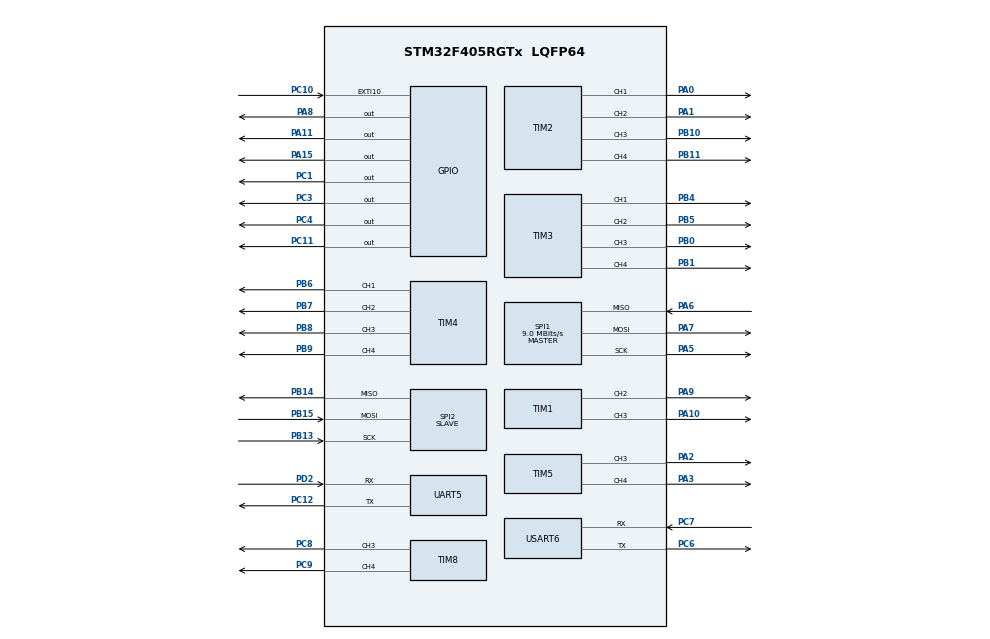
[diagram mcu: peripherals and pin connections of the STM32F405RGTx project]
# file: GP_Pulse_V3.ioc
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Mcu.Family=STM32F4
Mcu.Name=STM32F405RGTx
Mcu.Package=LQFP64
NVIC.EXTI15_10_IRQn=true\:9\:0\:true\:false\:true\:true\:true\:true
NVIC.PriorityGroup=NVIC_PRIORITYGROUP_4
NVIC.SPI1_IRQn=true\:10\:0\:true\:false\:true\:true\:true\:true
NVIC.TIM2_IRQn=true\:11\:0\:true\:false\:true\:true\:true\:true
NVIC.TIM3_IRQn=true\:11\:0\:true\:false\:true\:true\:true\:true
NVIC.TIM4_IRQn=true\:11\:0\:true\:false\:true\:true\:true\:true
NVIC.TIM5_IRQn=true\:11\:0\:true\:false\:true\:true\:true\:true
NVIC.TIM6_DAC_IRQn=true\:9\:0\:true\:false\:true\:true\:true\:true
NVIC.TIM7_IRQn=true\:12\:0\:true\:false\:true\:true\:true\:true
NVIC.TIM8_TRG_COM_TIM14_IRQn=true\:15\:0\:false\:false\:true\:false\:true\:true
NVIC.TIM8_UP_TIM13_IRQn=true\:11\:0\:true\:false\:true\:true\:true\:true
NVIC.TimeBase=TIM8_TRG_COM_TIM14_IRQn
NVIC.TimeBaseIP=TIM14
NVIC.UART5_IRQn=true\:14\:0\:true\:false\:true\:true\:true\:true
NVIC.USART6_IRQn=true\:14\:0\:true\:false\:true\:true\:true\:true
PA0-WKUP.Signal=S_TIM2_CH1_ETR
PA1.Signal=S_TIM2_CH2
PA10.Signal=S_TIM1_CH3
PA11.GPIO_PuPd=GPIO_PULLDOWN
PA11.Signal=GPIO_Output
PA13.Mode=Serial_Wire
PA13.Signal=SYS_JTMS-SWDIO
PA14.Mode=Serial_Wire
PA14.Signal=SYS_JTCK-SWCLK
PA15.GPIO_PuPd=GPIO_PULLDOWN
PA15.Signal=GPIO_Output
PA2.Signal=S_TIM5_CH3
PA3.Signal=S_TIM5_CH4
PA5.Mode=Full_Duplex_Master
PA5.Signal=SPI1_SCK
PA6.Mode=Full_Duplex_Master
PA6.Signal=SPI1_MISO
PA7.Mode=Full_Duplex_Master
PA7.Signal=SPI1_MOSI
PA8.GPIO_PuPd=GPIO_PULLDOWN
PA8.Signal=GPIO_Output
PA9.Signal=S_TIM1_CH2
PB0.Signal=S_TIM3_CH3
PB1.Signal=S_TIM3_CH4
PB10.Signal=S_TIM2_CH3
PB11.Signal=S_TIM2_CH4
PB13.Mode=Full_Duplex_Slave
PB13.Signal=SPI2_SCK
PB14.Mode=Full_Duplex_Slave
PB14.Signal=SPI2_MISO
PB15.Mode=Full_Duplex_Slave
PB15.Signal=SPI2_MOSI
PB4.Signal=S_TIM3_CH1
PB5.Signal=S_TIM3_CH2
PB6.Signal=S_TIM4_CH1
PB7.Signal=S_TIM4_CH2
PB8.Signal=S_TIM4_CH3
PB9.Signal=S_TIM4_CH4
PC1.GPIO_PuPd=GPIO_PULLDOWN
PC1.Signal=GPIO_Output
PC10.GPIO_ModeDefaultEXTI=GPIO_MODE_IT_FALLING
PC10.GPIO_PuPd=GPIO_PULLUP
PC10.Signal=GPXTI10
PC11.GPIO_PuPd=GPIO_PULLDOWN
PC11.Signal=GPIO_Output
PC12.Mode=Asynchronous
PC12.Signal=UART5_TX
PC3.GPIO_PuPd=GPIO_PULLDOWN
PC3.Signal=GPIO_Output
PC4.GPIO_PuPd=GPIO_PULLUP
PC4.GPIO_Speed=GPIO_SPEED_FREQ_VERY_HIGH
PC4.PinState=GPIO_PIN_SET
PC4.Signal=GPIO_Output
PC6.Mode=Asynchronous
PC6.Signal=USART6_TX
PC7.Mode=Asynchronous
PC7.Signal=USART6_RX
PC8.Signal=S_TIM8_CH3
PC9.Signal=S_TIM8_CH4
PD2.Mode=Asynchronous
PD2.Signal=UART5_RX
PH0-OSC_IN.Mode=HSE-External-Oscillator
PH0-OSC_IN.Signal=RCC_OSC_IN
PH1-OSC_OUT.Mode=HSE-External-Oscillator
PH1-OSC_OUT.Signal=RCC_OSC_OUT
ProjectManager.HeapSize=0x200
ProjectManager.StackSize=0x400
ProjectManager.TargetToolchain=STM32CubeIDE
RCC.48MHZClocksFreq_Value=36000000
RCC.AHBFreq_Value=72000000
RCC.APB1CLKDivider=RCC_HCLK_DIV2
RCC.APB1Freq_Value=36000000
RCC.APB1TimFreq_Value=72000000
RCC.APB2Freq_Value=72000000
RCC.APB2TimFreq_Value=72000000
RCC.CortexFreq_Value=72000000
RCC.HCLKFreq_Value=72000000
RCC.HSE_VALUE=8000000
RCC.HSI_VALUE=16000000
RCC.LSE_VALUE=32768
RCC.PLLM=4
RCC.PLLN=72
RCC.PLLSourceVirtual=RCC_PLLSOURCE_HSE
RCC.SYSCLKFreq_VALUE=72000000
RCC.SYSCLKSource=RCC_SYSCLKSOURCE_PLLCLK
RCC.VCOOutputFreq_Value=144000000
SH.S_TIM1_CH2.0=TIM1_CH2,PWM Generation2 CH2
SH.S_TIM1_CH3.0=TIM1_CH3,PWM Generation3 CH3
SH.S_TIM2_CH1_ETR.0=TIM2_CH1,PWM Generation1 CH1
SH.S_TIM2_CH2.0=TIM2_CH2,PWM Generation2 CH2
SH.S_TIM2_CH3.0=TIM2_CH3,PWM Generation3 CH3
SH.S_TIM2_CH4.0=TIM2_CH4,PWM Generation4 CH4
SH.S_TIM3_CH1.0=TIM3_CH1,PWM Generation1 CH1
SH.S_TIM3_CH2.0=TIM3_CH2,PWM Generation2 CH2
SH.S_TIM3_CH3.0=TIM3_CH3,PWM Generation3 CH3
SH.S_TIM3_CH4.0=TIM3_CH4,PWM Generation4 CH4
SH.S_TIM4_CH1.0=TIM4_CH1,PWM Generation1 CH1
SH.S_TIM4_CH2.0=TIM4_CH2,PWM Generation2 CH2
SH.S_TIM4_CH3.0=TIM4_CH3,PWM Generation3 CH3
SH.S_TIM4_CH4.0=TIM4_CH4,PWM Generation4 CH4
SH.S_TIM5_CH3.0=TIM5_CH3,PWM Generation3 CH3
SH.S_TIM5_CH4.0=TIM5_CH4,PWM Generation4 CH4
SH.S_TIM8_CH3.0=TIM8_CH3,Output Compare3 CH3
SH.S_TIM8_CH4.0=TIM8_CH4,PWM Generation4 CH4
SPI1.BaudRatePrescaler=SPI_BAUDRATEPRESCALER_8
SPI1.CLKPhase=SPI_PHASE_2EDGE
SPI1.CalculateBaudRate=9.0 MBits/s
SPI1.Direction=SPI_DIRECTION_2LINES
SPI1.Mode=SPI_MODE_MASTER
SPI1.VirtualType=VM_MASTER
SPI2.Direction=SPI_DIRECTION_2LINES
SPI2.Mode=SPI_MODE_SLAVE
SPI2.VirtualType=VM_SLAVE
TIM1.Channel-PWM\ Generation2\ CH2=TIM_CHANNEL_2
TIM1.Channel-PWM\ Generation3\ CH3=TIM_CHANNEL_3
TIM2.Channel-PWM\ Generation1\ CH1=TIM_CHANNEL_1
TIM2.Channel-PWM\ Generation2\ CH2=TIM_CHANNEL_2
TIM2.Channel-PWM\ Generation3\ CH3=TIM_CHANNEL_3
TIM2.Channel-PWM\ Generation4\ CH4=TIM_CHANNEL_4
TIM3.Channel-PWM\ Generation1\ CH1=TIM_CHANNEL_1
TIM3.Channel-PWM\ Generation2\ CH2=TIM_CHANNEL_2
TIM3.Channel-PWM\ Generation3\ CH3=TIM_CHANNEL_3
TIM3.Channel-PWM\ Generation4\ CH4=TIM_CHANNEL_4
TIM4.Channel-PWM\ Generation1\ CH1=TIM_CHANNEL_1
TIM4.Channel-PWM\ Generation2\ CH2=TIM_CHANNEL_2
TIM4.Channel-PWM\ Generation3\ CH3=TIM_CHANNEL_3
TIM4.Channel-PWM\ Generation4\ CH4=TIM_CHANNEL_4
TIM5.Channel-PWM\ Generation3\ CH3=TIM_CHANNEL_3
TIM5.Channel-PWM\ Generation4\ CH4=TIM_CHANNEL_4
TIM8.Channel-Output\ Compare3\ CH3=TIM_CHANNEL_3
TIM8.Channel-PWM\ Generation4\ CH4=TIM_CHANNEL_4
UART5.VirtualMode=Asynchronous
USART6.VirtualMode=VM_ASYNC
VP_SYS_VS_tim14.Mode=TIM14
VP_TIM6_VS_ClockSourceINT.Mode=Enable_Timer
VP_TIM7_VS_ClockSourceINT.Mode=Enable_Timer
board=custom

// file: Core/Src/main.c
/* USER CODE BEGIN Header */
/**
  ******************************************************************************
  * @file           : main.c
  * @brief          : Main program body
  ******************************************************************************
  * @attention
  *
  * Copyright (c) 2025 STMicroelectronics.
  * All rights reserved.
  *
  * This software is licensed under terms that can be found in the LICENSE file
  * in the root directory of this software component.
  * If no LICENSE file comes with this software, it is provided AS-IS.
  *
  ******************************************************************************
  */
/* USER CODE END Header */
#include "main.h"

/* USER CODE BEGIN Includes */
#include "app.h"
/* USER CODE END Includes */

void SystemClock_Config(void);
static void MX_GPIO_Init(void);
static void MX_SPI1_Init(void);
static void MX_SPI2_Init(void);
static void MX_TIM1_Init(void);
static void MX_TIM2_Init(void);
static void MX_TIM3_Init(void);
static void MX_TIM4_Init(void);
static void MX_TIM5_Init(void);
static void MX_TIM8_Init(void);
static void MX_UART5_Init(void);
static void MX_USART6_UART_Init(void);
static void MX_TIM6_Init(void);
static void MX_TIM7_Init(void);

int main(void)
{

  /* MCU Configuration--------------------------------------------------------*/

  /* Reset of all peripherals, Initializes the Flash interface and the Systick. */
  HAL_Init();

  /* Configure the system clock */
  SystemClock_Config();

  /* Initialize all configured peripherals */
  MX_GPIO_Init();
  MX_SPI1_Init();
  MX_SPI2_Init();
  MX_TIM1_Init();
  MX_TIM2_Init();
  MX_TIM3_Init();
  MX_TIM4_Init();
  MX_TIM5_Init();
  MX_TIM8_Init();
  MX_UART5_Init();
  MX_USART6_UART_Init();
  MX_TIM6_Init();
  MX_TIM7_Init();
  /* USER CODE BEGIN 2 */
  App_Main();
  /* USER CODE END 2 */

  /* Infinite loop */
  while (1)
  {

  }
}

void SystemClock_Config(void)
{
  LL_FLASH_SetLatency(LL_FLASH_LATENCY_2);
  while(LL_FLASH_GetLatency()!= LL_FLASH_LATENCY_2)
  {
  }
  LL_PWR_SetRegulVoltageScaling(LL_PWR_REGU_VOLTAGE_SCALE1);
  LL_RCC_HSE_Enable();

   /* Wait till HSE is ready */
  while(LL_RCC_HSE_IsReady() != 1)
  {

  }
  LL_RCC_PLL_ConfigDomain_SYS(LL_RCC_PLLSOURCE_HSE, LL_RCC_PLLM_DIV_4, 72, LL_RCC_PLLP_DIV_2);
  LL_RCC_PLL_Enable();

   /* Wait till PLL is ready */
  while(LL_RCC_PLL_IsReady() != 1)
  {

  }
  while (LL_PWR_IsActiveFlag_VOS() == 0)
  {
  }
  LL_RCC_SetAHBPrescaler(LL_RCC_SYSCLK_DIV_1);
  LL_RCC_SetAPB1Prescaler(LL_RCC_APB1_DIV_2);
  LL_RCC_SetAPB2Prescaler(LL_RCC_APB2_DIV_1);
  LL_RCC_SetSysClkSource(LL_RCC_SYS_CLKSOURCE_PLL);

   /* Wait till System clock is ready */
  while(LL_RCC_GetSysClkSource() != LL_RCC_SYS_CLKSOURCE_STATUS_PLL)
  {

  }
  LL_SetSystemCoreClock(72000000);

   /* Update the time base */
  if (HAL_InitTick (TICK_INT_PRIORITY) != HAL_OK)
  {
    Error_Handler();
  }
}

static void MX_SPI1_Init(void)
{

  LL_SPI_InitTypeDef SPI_InitStruct = {0};

  LL_GPIO_InitTypeDef GPIO_InitStruct = {0};

  /* Peripheral clock enable */
  LL_APB2_GRP1_EnableClock(LL_APB2_GRP1_PERIPH_SPI1);

  LL_AHB1_GRP1_EnableClock(LL_AHB1_GRP1_PERIPH_GPIOA);
  /**SPI1 GPIO Configuration
  PA5   ------> SPI1_SCK
  PA6   ------> SPI1_MISO
  PA7   ------> SPI1_MOSI
  */
  GPIO_InitStruct.Pin = LL_GPIO_PIN_5|LL_GPIO_PIN_6|LL_GPIO_PIN_7;
  GPIO_InitStruct.Mode = LL_GPIO_MODE_ALTERNATE;
  GPIO_InitStruct.Speed = LL_GPIO_SPEED_FREQ_VERY_HIGH;
  GPIO_InitStruct.OutputType = LL_GPIO_OUTPUT_PUSHPULL;
  GPIO_InitStruct.Pull = LL_GPIO_PULL_NO;
  GPIO_InitStruct.Alternate = LL_GPIO_AF_5;
  LL_GPIO_Init(GPIOA, &GPIO_InitStruct);

  /* SPI1 interrupt Init */
  NVIC_SetPriority(SPI1_IRQn, NVIC_EncodePriority(NVIC_GetPriorityGrouping(),10, 0));
  NVIC_EnableIRQ(SPI1_IRQn);

  /* SPI1 parameter configuration*/
  SPI_InitStruct.TransferDirection = LL_SPI_FULL_DUPLEX;
  SPI_InitStruct.Mode = LL_SPI_MODE_MASTER;
  SPI_InitStruct.DataWidth = LL_SPI_DATAWIDTH_8BIT;
  SPI_InitStruct.ClockPolarity = LL_SPI_POLARITY_LOW;
  SPI_InitStruct.ClockPhase = LL_SPI_PHASE_2EDGE;
  SPI_InitStruct.NSS = LL_SPI_NSS_SOFT;
  SPI_InitStruct.BaudRate = LL_SPI_BAUDRATEPRESCALER_DIV8;
  SPI_InitStruct.BitOrder = LL_SPI_MSB_FIRST;
  SPI_InitStruct.CRCCalculation = LL_SPI_CRCCALCULATION_DISABLE;
  SPI_InitStruct.CRCPoly = 10;
  LL_SPI_Init(SPI1, &SPI_InitStruct);
  LL_SPI_SetStandard(SPI1, LL_SPI_PROTOCOL_MOTOROLA);

}

static void MX_SPI2_Init(void)
{

  LL_SPI_InitTypeDef SPI_InitStruct = {0};

  LL_GPIO_InitTypeDef GPIO_InitStruct = {0};

  /* Peripheral clock enable */
  LL_APB1_GRP1_EnableClock(LL_APB1_GRP1_PERIPH_SPI2);

  LL_AHB1_GRP1_EnableClock(LL_AHB1_GRP1_PERIPH_GPIOB);
  /**SPI2 GPIO Configuration
  PB13   ------> SPI2_SCK
  PB14   ------> SPI2_MISO
  PB15   ------> SPI2_MOSI
  */
  GPIO_InitStruct.Pin = LL_GPIO_PIN_13|LL_GPIO_PIN_14|LL_GPIO_PIN_15;
  GPIO_InitStruct.Mode = LL_GPIO_MODE_ALTERNATE;
  GPIO_InitStruct.Speed = LL_GPIO_SPEED_FREQ_VERY_HIGH;
  GPIO_InitStruct.OutputType = LL_GPIO_OUTPUT_PUSHPULL;
  GPIO_InitStruct.Pull = LL_GPIO_PULL_NO;
  GPIO_InitStruct.Alternate = LL_GPIO_AF_5;
  LL_GPIO_Init(GPIOB, &GPIO_InitStruct);

  /* SPI2 parameter configuration*/
  SPI_InitStruct.TransferDirection = LL_SPI_FULL_DUPLEX;
  SPI_InitStruct.Mode = LL_SPI_MODE_SLAVE;
  SPI_InitStruct.DataWidth = LL_SPI_DATAWIDTH_8BIT;
  SPI_InitStruct.ClockPolarity = LL_SPI_POLARITY_LOW;
  SPI_InitStruct.ClockPhase = LL_SPI_PHASE_1EDGE;
  SPI_InitStruct.NSS = LL_SPI_NSS_SOFT;
  SPI_InitStruct.BitOrder = LL_SPI_MSB_FIRST;
  SPI_InitStruct.CRCCalculation = LL_SPI_CRCCALCULATION_DISABLE;
  SPI_InitStruct.CRCPoly = 10;
  LL_SPI_Init(SPI2, &SPI_InitStruct);
  LL_SPI_SetStandard(SPI2, LL_SPI_PROTOCOL_MOTOROLA);

}

static void MX_TIM1_Init(void)
{

  LL_TIM_InitTypeDef TIM_InitStruct = {0};
  LL_TIM_OC_InitTypeDef TIM_OC_InitStruct = {0};
  LL_TIM_BDTR_InitTypeDef TIM_BDTRInitStruct = {0};

  LL_GPIO_InitTypeDef GPIO_InitStruct = {0};

  /* Peripheral clock enable */
  LL_APB2_GRP1_EnableClock(LL_APB2_GRP1_PERIPH_TIM1);

  TIM_InitStruct.Prescaler = 0;
  TIM_InitStruct.CounterMode = LL_TIM_COUNTERMODE_UP;
  TIM_InitStruct.Autoreload = 65535;
  TIM_InitStruct.ClockDivision = LL_TIM_CLOCKDIVISION_DIV1;
  TIM_InitStruct.RepetitionCounter = 0;
  LL_TIM_Init(TIM1, &TIM_InitStruct);
  LL_TIM_DisableARRPreload(TIM1);
  LL_TIM_OC_EnablePreload(TIM1, LL_TIM_CHANNEL_CH2);
  TIM_OC_InitStruct.OCMode = LL_TIM_OCMODE_PWM1;
  TIM_OC_InitStruct.OCState = LL_TIM_OCSTATE_DISABLE;
  TIM_OC_InitStruct.OCNState = LL_TIM_OCSTATE_DISABLE;
  TIM_OC_InitStruct.CompareValue = 0;
  TIM_OC_InitStruct.OCPolarity = LL_TIM_OCPOLARITY_HIGH;
  TIM_OC_InitStruct.OCNPolarity = LL_TIM_OCPOLARITY_HIGH;
  TIM_OC_InitStruct.OCIdleState = LL_TIM_OCIDLESTATE_LOW;
  TIM_OC_InitStruct.OCNIdleState = LL_TIM_OCIDLESTATE_LOW;
  LL_TIM_OC_Init(TIM1, LL_TIM_CHANNEL_CH2, &TIM_OC_InitStruct);
  LL_TIM_OC_DisableFast(TIM1, LL_TIM_CHANNEL_CH2);
  LL_TIM_OC_EnablePreload(TIM1, LL_TIM_CHANNEL_CH3);
  LL_TIM_OC_Init(TIM1, LL_TIM_CHANNEL_CH3, &TIM_OC_InitStruct);
  LL_TIM_OC_DisableFast(TIM1, LL_TIM_CHANNEL_CH3);
  LL_TIM_SetTriggerOutput(TIM1, LL_TIM_TRGO_RESET);
  LL_TIM_DisableMasterSlaveMode(TIM1);
  TIM_BDTRInitStruct.OSSRState = LL_TIM_OSSR_DISABLE;
  TIM_BDTRInitStruct.OSSIState = LL_TIM_OSSI_DISABLE;
  TIM_BDTRInitStruct.LockLevel = LL_TIM_LOCKLEVEL_OFF;
  TIM_BDTRInitStruct.DeadTime = 0;
  TIM_BDTRInitStruct.BreakState = LL_TIM_BREAK_DISABLE;
  TIM_BDTRInitStruct.BreakPolarity = LL_TIM_BREAK_POLARITY_HIGH;
  TIM_BDTRInitStruct.AutomaticOutput = LL_TIM_AUTOMATICOUTPUT_DISABLE;
  LL_TIM_BDTR_Init(TIM1, &TIM_BDTRInitStruct);
  LL_AHB1_GRP1_EnableClock(LL_AHB1_GRP1_PERIPH_GPIOA);
  /**TIM1 GPIO Configuration
  PA9   ------> TIM1_CH2
  PA10   ------> TIM1_CH3
  */
  GPIO_InitStruct.Pin = LL_GPIO_PIN_9|LL_GPIO_PIN_10;
  GPIO_InitStruct.Mode = LL_GPIO_MODE_ALTERNATE;
  GPIO_InitStruct.Speed = LL_GPIO_SPEED_FREQ_LOW;
  GPIO_InitStruct.OutputType = LL_GPIO_OUTPUT_PUSHPULL;
  GPIO_InitStruct.Pull = LL_GPIO_PULL_NO;
  GPIO_InitStruct.Alternate = LL_GPIO_AF_1;
  LL_GPIO_Init(GPIOA, &GPIO_InitStruct);

}

static void MX_TIM2_Init(void)
{

  LL_TIM_InitTypeDef TIM_InitStruct = {0};
  LL_TIM_OC_InitTypeDef TIM_OC_InitStruct = {0};

  LL_GPIO_InitTypeDef GPIO_InitStruct = {0};

  /* Peripheral clock enable */
  LL_APB1_GRP1_EnableClock(LL_APB1_GRP1_PERIPH_TIM2);

  /* TIM2 interrupt Init */
  NVIC_SetPriority(TIM2_IRQn, NVIC_EncodePriority(NVIC_GetPriorityGrouping(),11, 0));
  NVIC_EnableIRQ(TIM2_IRQn);

  TIM_InitStruct.Prescaler = 0;
  TIM_InitStruct.CounterMode = LL_TIM_COUNTERMODE_UP;
  TIM_InitStruct.Autoreload = 4294967295;
  TIM_InitStruct.ClockDivision = LL_TIM_CLOCKDIVISION_DIV1;
  LL_TIM_Init(TIM2, &TIM_InitStruct);
  LL_TIM_DisableARRPreload(TIM2);
  LL_TIM_OC_EnablePreload(TIM2, LL_TIM_CHANNEL_CH1);
  TIM_OC_InitStruct.OCMode = LL_TIM_OCMODE_PWM1;
  TIM_OC_InitStruct.OCState = LL_TIM_OCSTATE_DISABLE;
  TIM_OC_InitStruct.OCNState = LL_TIM_OCSTATE_DISABLE;
  TIM_OC_InitStruct.CompareValue = 0;
  TIM_OC_InitStruct.OCPolarity = LL_TIM_OCPOLARITY_HIGH;
  LL_TIM_OC_Init(TIM2, LL_TIM_CHANNEL_CH1, &TIM_OC_InitStruct);
  LL_TIM_OC_DisableFast(TIM2, LL_TIM_CHANNEL_CH1);
  LL_TIM_OC_EnablePreload(TIM2, LL_TIM_CHANNEL_CH2);
  LL_TIM_OC_Init(TIM2, LL_TIM_CHANNEL_CH2, &TIM_OC_InitStruct);
  LL_TIM_OC_DisableFast(TIM2, LL_TIM_CHANNEL_CH2);
  LL_TIM_OC_EnablePreload(TIM2, LL_TIM_CHANNEL_CH3);
  LL_TIM_OC_Init(TIM2, LL_TIM_CHANNEL_CH3, &TIM_OC_InitStruct);
  LL_TIM_OC_DisableFast(TIM2, LL_TIM_CHANNEL_CH3);
  LL_TIM_OC_EnablePreload(TIM2, LL_TIM_CHANNEL_CH4);
  LL_TIM_OC_Init(TIM2, LL_TIM_CHANNEL_CH4, &TIM_OC_InitStruct);
  LL_TIM_OC_DisableFast(TIM2, LL_TIM_CHANNEL_CH4);
  LL_TIM_SetTriggerOutput(TIM2, LL_TIM_TRGO_RESET);
  LL_TIM_DisableMasterSlaveMode(TIM2);
  LL_AHB1_GRP1_EnableClock(LL_AHB1_GRP1_PERIPH_GPIOA);
  LL_AHB1_GRP1_EnableClock(LL_AHB1_GRP1_PERIPH_GPIOB);
  /**TIM2 GPIO Configuration
  PA0-WKUP   ------> TIM2_CH1
  PA1   ------> TIM2_CH2
  PB10   ------> TIM2_CH3
  PB11   ------> TIM2_CH4
  */
  GPIO_InitStruct.Pin = LL_GPIO_PIN_0|LL_GPIO_PIN_1;
  GPIO_InitStruct.Mode = LL_GPIO_MODE_ALTERNATE;
  GPIO_InitStruct.Speed = LL_GPIO_SPEED_FREQ_LOW;
  GPIO_InitStruct.OutputType = LL_GPIO_OUTPUT_PUSHPULL;
  GPIO_InitStruct.Pull = LL_GPIO_PULL_NO;
  GPIO_InitStruct.Alternate = LL_GPIO_AF_1;
  LL_GPIO_Init(GPIOA, &GPIO_InitStruct);

  GPIO_InitStruct.Pin = LL_GPIO_PIN_10|LL_GPIO_PIN_11;
  GPIO_InitStruct.Mode = LL_GPIO_MODE_ALTERNATE;
  GPIO_InitStruct.Speed = LL_GPIO_SPEED_FREQ_LOW;
  GPIO_InitStruct.OutputType = LL_GPIO_OUTPUT_PUSHPULL;
  GPIO_InitStruct.Pull = LL_GPIO_PULL_NO;
  GPIO_InitStruct.Alternate = LL_GPIO_AF_1;
  LL_GPIO_Init(GPIOB, &GPIO_InitStruct);

}

static void MX_TIM3_Init(void)
{

  LL_TIM_InitTypeDef TIM_InitStruct = {0};
  LL_TIM_OC_InitTypeDef TIM_OC_InitStruct = {0};

  LL_GPIO_InitTypeDef GPIO_InitStruct = {0};

  /* Peripheral clock enable */
  LL_APB1_GRP1_EnableClock(LL_APB1_GRP1_PERIPH_TIM3);

  /* TIM3 interrupt Init */
  NVIC_SetPriority(TIM3_IRQn, NVIC_EncodePriority(NVIC_GetPriorityGrouping(),11, 0));
  NVIC_EnableIRQ(TIM3_IRQn);

  TIM_InitStruct.Prescaler = 0;
  TIM_InitStruct.CounterMode = LL_TIM_COUNTERMODE_UP;
  TIM_InitStruct.Autoreload = 65535;
  TIM_InitStruct.ClockDivision = LL_TIM_CLOCKDIVISION_DIV1;
  LL_TIM_Init(TIM3, &TIM_InitStruct);
  LL_TIM_DisableARRPreload(TIM3);
  LL_TIM_OC_EnablePreload(TIM3, LL_TIM_CHANNEL_CH1);
  TIM_OC_InitStruct.OCMode = LL_TIM_OCMODE_PWM1;
  TIM_OC_InitStruct.OCState = LL_TIM_OCSTATE_DISABLE;
  TIM_OC_InitStruct.OCNState = LL_TIM_OCSTATE_DISABLE;
  TIM_OC_InitStruct.CompareValue = 0;
  TIM_OC_InitStruct.OCPolarity = LL_TIM_OCPOLARITY_HIGH;
  LL_TIM_OC_Init(TIM3, LL_TIM_CHANNEL_CH1, &TIM_OC_InitStruct);
  LL_TIM_OC_DisableFast(TIM3, LL_TIM_CHANNEL_CH1);
  LL_TIM_OC_EnablePreload(TIM3, LL_TIM_CHANNEL_CH2);
  LL_TIM_OC_Init(TIM3, LL_TIM_CHANNEL_CH2, &TIM_OC_InitStruct);
  LL_TIM_OC_DisableFast(TIM3, LL_TIM_CHANNEL_CH2);
  LL_TIM_OC_EnablePreload(TIM3, LL_TIM_CHANNEL_CH3);
  LL_TIM_OC_Init(TIM3, LL_TIM_CHANNEL_CH3, &TIM_OC_InitStruct);
  LL_TIM_OC_DisableFast(TIM3, LL_TIM_CHANNEL_CH3);
  LL_TIM_OC_EnablePreload(TIM3, LL_TIM_CHANNEL_CH4);
  LL_TIM_OC_Init(TIM3, LL_TIM_CHANNEL_CH4, &TIM_OC_InitStruct);
  LL_TIM_OC_DisableFast(TIM3, LL_TIM_CHANNEL_CH4);
  LL_TIM_SetTriggerOutput(TIM3, LL_TIM_TRGO_RESET);
  LL_TIM_DisableMasterSlaveMode(TIM3);
  LL_AHB1_GRP1_EnableClock(LL_AHB1_GRP1_PERIPH_GPIOB);
  /**TIM3 GPIO Configuration
  PB0   ------> TIM3_CH3
  PB1   ------> TIM3_CH4
  PB4   ------> TIM3_CH1
  PB5   ------> TIM3_CH2
  */
  GPIO_InitStruct.Pin = LL_GPIO_PIN_0|LL_GPIO_PIN_1|LL_GPIO_PIN_4|LL_GPIO_PIN_5;
  GPIO_InitStruct.Mode = LL_GPIO_MODE_ALTERNATE;
  GPIO_InitStruct.Speed = LL_GPIO_SPEED_FREQ_LOW;
  GPIO_InitStruct.OutputType = LL_GPIO_OUTPUT_PUSHPULL;
  GPIO_InitStruct.Pull = LL_GPIO_PULL_NO;
  GPIO_InitStruct.Alternate = LL_GPIO_AF_2;
  LL_GPIO_Init(GPIOB, &GPIO_InitStruct);

}

static void MX_TIM4_Init(void)
{

  LL_TIM_InitTypeDef TIM_InitStruct = {0};
  LL_TIM_OC_InitTypeDef TIM_OC_InitStruct = {0};

  LL_GPIO_InitTypeDef GPIO_InitStruct = {0};

  /* Peripheral clock enable */
  LL_APB1_GRP1_EnableClock(LL_APB1_GRP1_PERIPH_TIM4);

  /* TIM4 interrupt Init */
  NVIC_SetPriority(TIM4_IRQn, NVIC_EncodePriority(NVIC_GetPriorityGrouping(),11, 0));
  NVIC_EnableIRQ(TIM4_IRQn);

  TIM_InitStruct.Prescaler = 0;
  TIM_InitStruct.CounterMode = LL_TIM_COUNTERMODE_UP;
  TIM_InitStruct.Autoreload = 65535;
  TIM_InitStruct.ClockDivision = LL_TIM_CLOCKDIVISION_DIV1;
  LL_TIM_Init(TIM4, &TIM_InitStruct);
  LL_TIM_DisableARRPreload(TIM4);
  LL_TIM_OC_EnablePreload(TIM4, LL_TIM_CHANNEL_CH1);
  TIM_OC_InitStruct.OCMode = LL_TIM_OCMODE_PWM1;
  TIM_OC_InitStruct.OCState = LL_TIM_OCSTATE_DISABLE;
  TIM_OC_InitStruct.OCNState = LL_TIM_OCSTATE_DISABLE;
  TIM_OC_InitStruct.CompareValue = 0;
  TIM_OC_InitStruct.OCPolarity = LL_TIM_OCPOLARITY_HIGH;
  LL_TIM_OC_Init(TIM4, LL_TIM_CHANNEL_CH1, &TIM_OC_InitStruct);
  LL_TIM_OC_DisableFast(TIM4, LL_TIM_CHANNEL_CH1);
  LL_TIM_OC_EnablePreload(TIM4, LL_TIM_CHANNEL_CH2);
  LL_TIM_OC_Init(TIM4, LL_TIM_CHANNEL_CH2, &TIM_OC_InitStruct);
  LL_TIM_OC_DisableFast(TIM4, LL_TIM_CHANNEL_CH2);
  LL_TIM_OC_EnablePreload(TIM4, LL_TIM_CHANNEL_CH3);
  LL_TIM_OC_Init(TIM4, LL_TIM_CHANNEL_CH3, &TIM_OC_InitStruct);
  LL_TIM_OC_DisableFast(TIM4, LL_TIM_CHANNEL_CH3);
  LL_TIM_OC_EnablePreload(TIM4, LL_TIM_CHANNEL_CH4);
  LL_TIM_OC_Init(TIM4, LL_TIM_CHANNEL_CH4, &TIM_OC_InitStruct);
  LL_TIM_OC_DisableFast(TIM4, LL_TIM_CHANNEL_CH4);
  LL_TIM_SetTriggerOutput(TIM4, LL_TIM_TRGO_RESET);
  LL_TIM_DisableMasterSlaveMode(TIM4);
  LL_AHB1_GRP1_EnableClock(LL_AHB1_GRP1_PERIPH_GPIOB);
  /**TIM4 GPIO Configuration
  PB6   ------> TIM4_CH1
  PB7   ------> TIM4_CH2
  PB8   ------> TIM4_CH3
  PB9   ------> TIM4_CH4
  */
  GPIO_InitStruct.Pin = LL_GPIO_PIN_6|LL_GPIO_PIN_7|LL_GPIO_PIN_8|LL_GPIO_PIN_9;
  GPIO_InitStruct.Mode = LL_GPIO_MODE_ALTERNATE;
  GPIO_InitStruct.Speed = LL_GPIO_SPEED_FREQ_LOW;
  GPIO_InitStruct.OutputType = LL_GPIO_OUTPUT_PUSHPULL;
  GPIO_InitStruct.Pull = LL_GPIO_PULL_NO;
  GPIO_InitStruct.Alternate = LL_GPIO_AF_2;
  LL_GPIO_Init(GPIOB, &GPIO_InitStruct);

}

static void MX_TIM5_Init(void)
{

  LL_TIM_InitTypeDef TIM_InitStruct = {0};
  LL_TIM_OC_InitTypeDef TIM_OC_InitStruct = {0};

  LL_GPIO_InitTypeDef GPIO_InitStruct = {0};

  /* Peripheral clock enable */
  LL_APB1_GRP1_EnableClock(LL_APB1_GRP1_PERIPH_TIM5);

  /* TIM5 interrupt Init */
  NVIC_SetPriority(TIM5_IRQn, NVIC_EncodePriority(NVIC_GetPriorityGrouping(),11, 0));
  NVIC_EnableIRQ(TIM5_IRQn);

  TIM_InitStruct.Prescaler = 0;
  TIM_InitStruct.CounterMode = LL_TIM_COUNTERMODE_UP;
  TIM_InitStruct.Autoreload = 4294967295;
  TIM_InitStruct.ClockDivision = LL_TIM_CLOCKDIVISION_DIV1;
  LL_TIM_Init(TIM5, &TIM_InitStruct);
  LL_TIM_DisableARRPreload(TIM5);
  LL_TIM_OC_EnablePreload(TIM5, LL_TIM_CHANNEL_CH3);
  TIM_OC_InitStruct.OCMode = LL_TIM_OCMODE_PWM1;
  TIM_OC_InitStruct.OCState = LL_TIM_OCSTATE_DISABLE;
  TIM_OC_InitStruct.OCNState = LL_TIM_OCSTATE_DISABLE;
  TIM_OC_InitStruct.CompareValue = 0;
  TIM_OC_InitStruct.OCPolarity = LL_TIM_OCPOLARITY_HIGH;
  LL_TIM_OC_Init(TIM5, LL_TIM_CHANNEL_CH3, &TIM_OC_InitStruct);
  LL_TIM_OC_DisableFast(TIM5, LL_TIM_CHANNEL_CH3);
  LL_TIM_OC_EnablePreload(TIM5, LL_TIM_CHANNEL_CH4);
  LL_TIM_OC_Init(TIM5, LL_TIM_CHANNEL_CH4, &TIM_OC_InitStruct);
  LL_TIM_OC_DisableFast(TIM5, LL_TIM_CHANNEL_CH4);
  LL_TIM_SetTriggerOutput(TIM5, LL_TIM_TRGO_RESET);
  LL_TIM_DisableMasterSlaveMode(TIM5);
  LL_AHB1_GRP1_EnableClock(LL_AHB1_GRP1_PERIPH_GPIOA);
  /**TIM5 GPIO Configuration
  PA2   ------> TIM5_CH3
  PA3   ------> TIM5_CH4
  */
  GPIO_InitStruct.Pin = LL_GPIO_PIN_2|LL_GPIO_PIN_3;
  GPIO_InitStruct.Mode = LL_GPIO_MODE_ALTERNATE;
  GPIO_InitStruct.Speed = LL_GPIO_SPEED_FREQ_LOW;
  GPIO_InitStruct.OutputType = LL_GPIO_OUTPUT_PUSHPULL;
  GPIO_InitStruct.Pull = LL_GPIO_PULL_NO;
  GPIO_InitStruct.Alternate = LL_GPIO_AF_2;
  LL_GPIO_Init(GPIOA, &GPIO_InitStruct);

}

static void MX_TIM6_Init(void)
{

  LL_TIM_InitTypeDef TIM_InitStruct = {0};

  /* Peripheral clock enable */
  LL_APB1_GRP1_EnableClock(LL_APB1_GRP1_PERIPH_TIM6);

  /* TIM6 interrupt Init */
  NVIC_SetPriority(TIM6_DAC_IRQn, NVIC_EncodePriority(NVIC_GetPriorityGrouping(),9, 0));
  NVIC_EnableIRQ(TIM6_DAC_IRQn);

  TIM_InitStruct.Prescaler = 0;
  TIM_InitStruct.CounterMode = LL_TIM_COUNTERMODE_UP;
  TIM_InitStruct.Autoreload = 65535;
  LL_TIM_Init(TIM6, &TIM_InitStruct);
  LL_TIM_DisableARRPreload(TIM6);
  LL_TIM_SetTriggerOutput(TIM6, LL_TIM_TRGO_RESET);
  LL_TIM_DisableMasterSlaveMode(TIM6);

}

static void MX_TIM7_Init(void)
{

  LL_TIM_InitTypeDef TIM_InitStruct = {0};

  /* Peripheral clock enable */
  LL_APB1_GRP1_EnableClock(LL_APB1_GRP1_PERIPH_TIM7);

  /* TIM7 interrupt Init */
  NVIC_SetPriority(TIM7_IRQn, NVIC_EncodePriority(NVIC_GetPriorityGrouping(),12, 0));
  NVIC_EnableIRQ(TIM7_IRQn);

  TIM_InitStruct.Prescaler = 0;
  TIM_InitStruct.CounterMode = LL_TIM_COUNTERMODE_UP;
  TIM_InitStruct.Autoreload = 65535;
  LL_TIM_Init(TIM7, &TIM_InitStruct);
  LL_TIM_DisableARRPreload(TIM7);
  LL_TIM_SetTriggerOutput(TIM7, LL_TIM_TRGO_RESET);
  LL_TIM_DisableMasterSlaveMode(TIM7);

}

static void MX_TIM8_Init(void)
{

  LL_TIM_InitTypeDef TIM_InitStruct = {0};
  LL_TIM_OC_InitTypeDef TIM_OC_InitStruct = {0};
  LL_TIM_BDTR_InitTypeDef TIM_BDTRInitStruct = {0};

  LL_GPIO_InitTypeDef GPIO_InitStruct = {0};

  /* Peripheral clock enable */
  LL_APB2_GRP1_EnableClock(LL_APB2_GRP1_PERIPH_TIM8);

  /* TIM8 interrupt Init */
  NVIC_SetPriority(TIM8_UP_TIM13_IRQn, NVIC_EncodePriority(NVIC_GetPriorityGrouping(),11, 0));
  NVIC_EnableIRQ(TIM8_UP_TIM13_IRQn);
  NVIC_SetPriority(TIM8_TRG_COM_TIM14_IRQn, NVIC_EncodePriority(NVIC_GetPriorityGrouping(),15, 0));
  NVIC_EnableIRQ(TIM8_TRG_COM_TIM14_IRQn);

  TIM_InitStruct.Prescaler = 0;
  TIM_InitStruct.CounterMode = LL_TIM_COUNTERMODE_UP;
  TIM_InitStruct.Autoreload = 65535;
  TIM_InitStruct.ClockDivision = LL_TIM_CLOCKDIVISION_DIV1;
  TIM_InitStruct.RepetitionCounter = 0;
  LL_TIM_Init(TIM8, &TIM_InitStruct);
  LL_TIM_DisableARRPreload(TIM8);
  TIM_OC_InitStruct.OCMode = LL_TIM_OCMODE_FROZEN;
  TIM_OC_InitStruct.OCState = LL_TIM_OCSTATE_DISABLE;
  TIM_OC_InitStruct.OCNState = LL_TIM_OCSTATE_DISABLE;
  TIM_OC_InitStruct.CompareValue = 0;
  TIM_OC_InitStruct.OCPolarity = LL_TIM_OCPOLARITY_HIGH;
  TIM_OC_InitStruct.OCNPolarity = LL_TIM_OCPOLARITY_HIGH;
  TIM_OC_InitStruct.OCIdleState = LL_TIM_OCIDLESTATE_LOW;
  TIM_OC_InitStruct.OCNIdleState = LL_TIM_OCIDLESTATE_LOW;
  LL_TIM_OC_Init(TIM8, LL_TIM_CHANNEL_CH3, &TIM_OC_InitStruct);
  LL_TIM_OC_DisableFast(TIM8, LL_TIM_CHANNEL_CH3);
  LL_TIM_OC_EnablePreload(TIM8, LL_TIM_CHANNEL_CH4);
  TIM_OC_InitStruct.OCMode = LL_TIM_OCMODE_PWM1;
  LL_TIM_OC_Init(TIM8, LL_TIM_CHANNEL_CH4, &TIM_OC_InitStruct);
  LL_TIM_OC_DisableFast(TIM8, LL_TIM_CHANNEL_CH4);
  LL_TIM_SetTriggerOutput(TIM8, LL_TIM_TRGO_RESET);
  LL_TIM_DisableMasterSlaveMode(TIM8);
  TIM_BDTRInitStruct.OSSRState = LL_TIM_OSSR_DISABLE;
  TIM_BDTRInitStruct.OSSIState = LL_TIM_OSSI_DISABLE;
  TIM_BDTRInitStruct.LockLevel = LL_TIM_LOCKLEVEL_OFF;
  TIM_BDTRInitStruct.DeadTime = 0;
  TIM_BDTRInitStruct.BreakState = LL_TIM_BREAK_DISABLE;
  TIM_BDTRInitStruct.BreakPolarity = LL_TIM_BREAK_POLARITY_HIGH;
  TIM_BDTRInitStruct.AutomaticOutput = LL_TIM_AUTOMATICOUTPUT_DISABLE;
  LL_TIM_BDTR_Init(TIM8, &TIM_BDTRInitStruct);
  LL_AHB1_GRP1_EnableClock(LL_AHB1_GRP1_PERIPH_GPIOC);
  /**TIM8 GPIO Configuration
  PC8   ------> TIM8_CH3
  PC9   ------> TIM8_CH4
  */
  GPIO_InitStruct.Pin = LL_GPIO_PIN_8|LL_GPIO_PIN_9;
  GPIO_InitStruct.Mode = LL_GPIO_MODE_ALTERNATE;
  GPIO_InitStruct.Speed = LL_GPIO_SPEED_FREQ_LOW;
  GPIO_InitStruct.OutputType = LL_GPIO_OUTPUT_PUSHPULL;
  GPIO_InitStruct.Pull = LL_GPIO_PULL_NO;
  GPIO_InitStruct.Alternate = LL_GPIO_AF_3;
  LL_GPIO_Init(GPIOC, &GPIO_InitStruct);

}

static void MX_UART5_Init(void)
{

  LL_USART_InitTypeDef USART_InitStruct = {0};

  LL_GPIO_InitTypeDef GPIO_InitStruct = {0};

  /* Peripheral clock enable */
  LL_APB1_GRP1_EnableClock(LL_APB1_GRP1_PERIPH_UART5);

  LL_AHB1_GRP1_EnableClock(LL_AHB1_GRP1_PERIPH_GPIOC);
  LL_AHB1_GRP1_EnableClock(LL_AHB1_GRP1_PERIPH_GPIOD);
  /**UART5 GPIO Configuration
  PC12   ------> UART5_TX
  PD2   ------> UART5_RX
  */
  GPIO_InitStruct.Pin = LL_GPIO_PIN_12;
  GPIO_InitStruct.Mode = LL_GPIO_MODE_ALTERNATE;
  GPIO_InitStruct.Speed = LL_GPIO_SPEED_FREQ_VERY_HIGH;
  GPIO_InitStruct.OutputType = LL_GPIO_OUTPUT_PUSHPULL;
  GPIO_InitStruct.Pull = LL_GPIO_PULL_NO;
  GPIO_InitStruct.Alternate = LL_GPIO_AF_8;
  LL_GPIO_Init(GPIOC, &GPIO_InitStruct);

  GPIO_InitStruct.Pin = LL_GPIO_PIN_2;
  GPIO_InitStruct.Mode = LL_GPIO_MODE_ALTERNATE;
  GPIO_InitStruct.Speed = LL_GPIO_SPEED_FREQ_VERY_HIGH;
  GPIO_InitStruct.OutputType = LL_GPIO_OUTPUT_PUSHPULL;
  GPIO_InitStruct.Pull = LL_GPIO_PULL_NO;
  GPIO_InitStruct.Alternate = LL_GPIO_AF_8;
  LL_GPIO_Init(GPIOD, &GPIO_InitStruct);

  /* UART5 interrupt Init */
  NVIC_SetPriority(UART5_IRQn, NVIC_EncodePriority(NVIC_GetPriorityGrouping(),14, 0));
  NVIC_EnableIRQ(UART5_IRQn);

  USART_InitStruct.BaudRate = 115200;
  USART_InitStruct.DataWidth = LL_USART_DATAWIDTH_8B;
  USART_InitStruct.StopBits = LL_USART_STOPBITS_1;
  USART_InitStruct.Parity = LL_USART_PARITY_NONE;
  USART_InitStruct.TransferDirection = LL_USART_DIRECTION_TX_RX;
  USART_InitStruct.HardwareFlowControl = LL_USART_HWCONTROL_NONE;
  USART_InitStruct.OverSampling = LL_USART_OVERSAMPLING_16;
  LL_USART_Init(UART5, &USART_InitStruct);
  LL_USART_ConfigAsyncMode(UART5);
  LL_USART_Enable(UART5);

}

static void MX_USART6_UART_Init(void)
{

  LL_USART_InitTypeDef USART_InitStruct = {0};

  LL_GPIO_InitTypeDef GPIO_InitStruct = {0};

  /* Peripheral clock enable */
  LL_APB2_GRP1_EnableClock(LL_APB2_GRP1_PERIPH_USART6);

  LL_AHB1_GRP1_EnableClock(LL_AHB1_GRP1_PERIPH_GPIOC);
  /**USART6 GPIO Configuration
  PC6   ------> USART6_TX
  PC7   ------> USART6_RX
  */
  GPIO_InitStruct.Pin = LL_GPIO_PIN_6|LL_GPIO_PIN_7;
  GPIO_InitStruct.Mode = LL_GPIO_MODE_ALTERNATE;
  GPIO_InitStruct.Speed = LL_GPIO_SPEED_FREQ_VERY_HIGH;
  GPIO_InitStruct.OutputType = LL_GPIO_OUTPUT_PUSHPULL;
  GPIO_InitStruct.Pull = LL_GPIO_PULL_NO;
  GPIO_InitStruct.Alternate = LL_GPIO_AF_8;
  LL_GPIO_Init(GPIOC, &GPIO_InitStruct);

  /* USART6 interrupt Init */
  NVIC_SetPriority(USART6_IRQn, NVIC_EncodePriority(NVIC_GetPriorityGrouping(),14, 0));
  NVIC_EnableIRQ(USART6_IRQn);

  USART_InitStruct.BaudRate = 115200;
  USART_InitStruct.DataWidth = LL_USART_DATAWIDTH_8B;
  USART_InitStruct.StopBits = LL_USART_STOPBITS_1;
  USART_InitStruct.Parity = LL_USART_PARITY_NONE;
  USART_InitStruct.TransferDirection = LL_USART_DIRECTION_TX_RX;
  USART_InitStruct.HardwareFlowControl = LL_USART_HWCONTROL_NONE;
  USART_InitStruct.OverSampling = LL_USART_OVERSAMPLING_16;
  LL_USART_Init(USART6, &USART_InitStruct);
  LL_USART_ConfigAsyncMode(USART6);
  LL_USART_Enable(USART6);

}

static void MX_GPIO_Init(void)
{
  LL_EXTI_InitTypeDef EXTI_InitStruct = {0};
  LL_GPIO_InitTypeDef GPIO_InitStruct = {0};

  /* GPIO Ports Clock Enable */
  LL_AHB1_GRP1_EnableClock(LL_AHB1_GRP1_PERIPH_GPIOH);
  LL_AHB1_GRP1_EnableClock(LL_AHB1_GRP1_PERIPH_GPIOC);
  LL_AHB1_GRP1_EnableClock(LL_AHB1_GRP1_PERIPH_GPIOA);
  LL_AHB1_GRP1_EnableClock(LL_AHB1_GRP1_PERIPH_GPIOB);
  LL_AHB1_GRP1_EnableClock(LL_AHB1_GRP1_PERIPH_GPIOD);

  /**/
  LL_GPIO_ResetOutputPin(GPIOC, LL_GPIO_PIN_1|LL_GPIO_PIN_3|LL_GPIO_PIN_11);

  /**/
  LL_GPIO_ResetOutputPin(GPIOA, LL_GPIO_PIN_8|LL_GPIO_PIN_11|LL_GPIO_PIN_15);

  /**/
  LL_GPIO_SetOutputPin(GPIOC, LL_GPIO_PIN_4);

  /**/
  GPIO_InitStruct.Pin = LL_GPIO_PIN_1|LL_GPIO_PIN_3|LL_GPIO_PIN_11;
  GPIO_InitStruct.Mode = LL_GPIO_MODE_OUTPUT;
  GPIO_InitStruct.Speed = LL_GPIO_SPEED_FREQ_LOW;
  GPIO_InitStruct.OutputType = LL_GPIO_OUTPUT_PUSHPULL;
  GPIO_InitStruct.Pull = LL_GPIO_PULL_DOWN;
  LL_GPIO_Init(GPIOC, &GPIO_InitStruct);

  /**/
  GPIO_InitStruct.Pin = LL_GPIO_PIN_4;
  GPIO_InitStruct.Mode = LL_GPIO_MODE_OUTPUT;
  GPIO_InitStruct.Speed = LL_GPIO_SPEED_FREQ_VERY_HIGH;
  GPIO_InitStruct.OutputType = LL_GPIO_OUTPUT_PUSHPULL;
  GPIO_InitStruct.Pull = LL_GPIO_PULL_UP;
  LL_GPIO_Init(GPIOC, &GPIO_InitStruct);

  /**/
  GPIO_InitStruct.Pin = LL_GPIO_PIN_8|LL_GPIO_PIN_11|LL_GPIO_PIN_15;
  GPIO_InitStruct.Mode = LL_GPIO_MODE_OUTPUT;
  GPIO_InitStruct.Speed = LL_GPIO_SPEED_FREQ_LOW;
  GPIO_InitStruct.OutputType = LL_GPIO_OUTPUT_PUSHPULL;
  GPIO_InitStruct.Pull = LL_GPIO_PULL_DOWN;
  LL_GPIO_Init(GPIOA, &GPIO_InitStruct);

  /**/
  LL_SYSCFG_SetEXTISource(LL_SYSCFG_EXTI_PORTC, LL_SYSCFG_EXTI_LINE10);

  /**/
  EXTI_InitStruct.Line_0_31 = LL_EXTI_LINE_10;
  EXTI_InitStruct.LineCommand = ENABLE;
  EXTI_InitStruct.Mode = LL_EXTI_MODE_IT;
  EXTI_InitStruct.Trigger = LL_EXTI_TRIGGER_FALLING;
  LL_EXTI_Init(&EXTI_InitStruct);

  /**/
  LL_GPIO_SetPinPull(GPIOC, LL_GPIO_PIN_10, LL_GPIO_PULL_UP);

  /**/
  LL_GPIO_SetPinMode(GPIOC, LL_GPIO_PIN_10, LL_GPIO_MODE_INPUT);

  /* EXTI interrupt init*/
  NVIC_SetPriority(EXTI15_10_IRQn, NVIC_EncodePriority(NVIC_GetPriorityGrouping(),9, 0));
  NVIC_EnableIRQ(EXTI15_10_IRQn);

}

void HAL_TIM_PeriodElapsedCallback(TIM_HandleTypeDef *htim)
{
  if (htim->Instance == TIM14) {
    HAL_IncTick();
  }
}

void Error_Handler(void)
{
  __disable_irq();
  while (1)
  {
  }
}
